# FM33FH0XX register map
File version: 1.0
CPU: SC000 r1p0, little endian, no MPU, no FPU, 3 interrupt priority bits
Registers are 32-bit, read-write, reset 0x0 unless marked. A register's access mark holds for its fields unless they carry their own. Offsets are from the block's base; [hi:lo] are bit positions; {n}, {i} and the like mark numbered series.

## GPIO_COMMON — GPIO module information
Base 0x40000E40
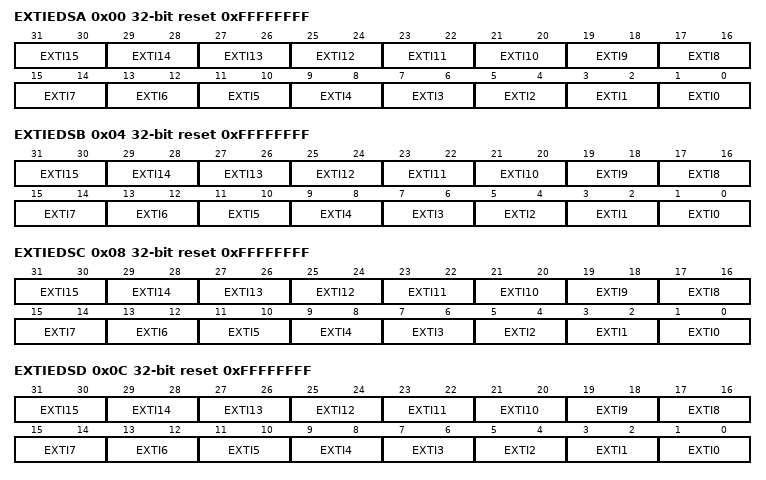
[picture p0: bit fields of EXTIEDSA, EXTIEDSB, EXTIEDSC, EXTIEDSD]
0x00 EXTIEDSA reset 0xFFFFFFFF
  [2n+1:2n] EXTI{n} (n=0..15) — EXTI{n} field description
0x04 EXTIEDSB reset 0xFFFFFFFF
  [2n+1:2n] EXTI{n} (n=0..15) — EXTI{n} field description
0x08 EXTIEDSC reset 0xFFFFFFFF
  [2n+1:2n] EXTI{n} (n=0..15) — EXTI{n} field description
0x0C EXTIEDSD reset 0xFFFFFFFF
  [2n+1:2n] EXTI{n} (n=0..15) — EXTI{n} field description
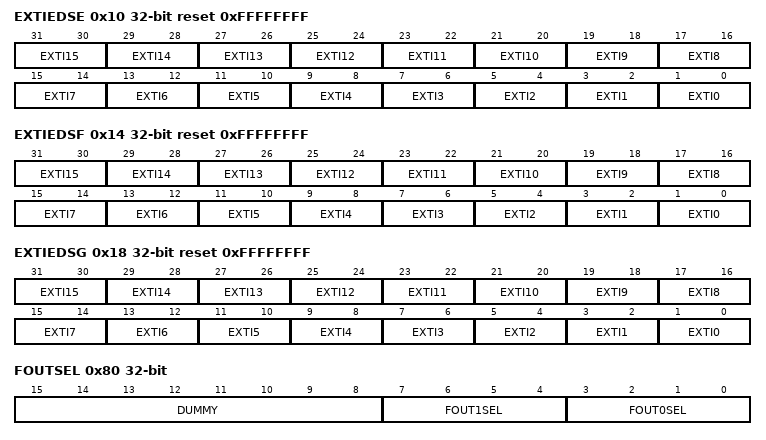
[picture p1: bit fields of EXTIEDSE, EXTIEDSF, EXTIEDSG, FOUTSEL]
0x10 EXTIEDSE reset 0xFFFFFFFF
  [2n+1:2n] EXTI{n} (n=0..15) — EXTI{n} field description
0x14 EXTIEDSF reset 0xFFFFFFFF
  [2n+1:2n] EXTI{n} (n=0..15) — EXTI{n} field description
0x18 EXTIEDSG reset 0xFFFFFFFF
  [2n+1:2n] EXTI{n} (n=0..15) — EXTI{n} field description
0x24 EXTIDFAB
  [31:0] DFAB — DFAB field description
0x28 EXTIDFCD
  [31:0] DFCD — DFCD field description
0x2C EXTIDFEF
  [31:0] DFEF — DFEF field description
0x30 EXTIDFGH
  [15:0] DFGH — DFGH field description
0x38 EXTIISRAB
  [31:0] ISRAB — ISRAB field description
0x3C EXTIISRCD
  [31:0] ISRCD — ISRCD field description
0x40 EXTIISREF
  [31:0] ISREF — ISREF field description
0x44 EXTIISRGH
  [15:0] ISRGH — ISRGH field description
0x4C EXTI_DIAB
  [31:0] DIAB — DIAB field description
0x50 EXTIDICD
  [31:0] DICD — DICD field description
0x54 EXTIDIEF
  [31:0] DIEF — DIEF field description
0x58 EXTIDIGH
  [15:0] DIGH — DIGH field description
0x80 FOUTSEL
  [15:8] DUMMY — DUMMY field description
  [7:4] FOUT1SEL — FOUT1SEL field description
  [3:0] FOUT0SEL — FOUT0SEL field description
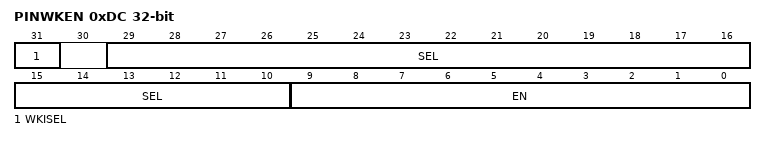
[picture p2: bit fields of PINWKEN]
0xDC PINWKEN
  [31] WKISEL — WKISEL field description
  [29:10] SEL — SEL field description
  [9:0] EN — EN field description

## GPIOA — GPIOA module information
Base 0x40000C00
Same registers: GPIOB 0x40000C40, GPIOC 0x40000C80, GPIOD 0x40000CC0, GPIOE 0x40000D00, GPIOF 0x40000D40, GPIOG 0x40000D80, GPIOH 0x40000DC0
0x00 INEN reset 0xC000
  [15:0] INEN — INEN field description
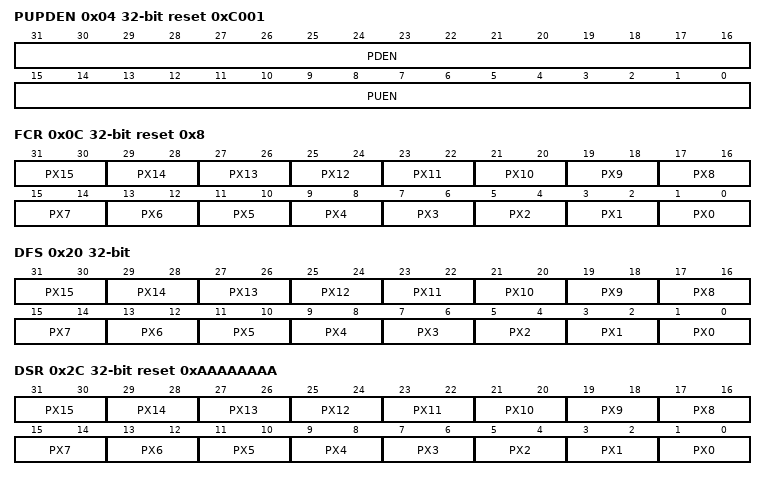
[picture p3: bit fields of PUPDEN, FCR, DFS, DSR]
0x04 PUPDEN reset 0xC001
  [31:16] PDEN — PDEN field description
  [15:0] PUEN — PUEN field description
0x08 ODEN
  [15:0] ODEN — ODEN field description
0x0C FCR reset 0x8
  [2n+1:2n] PX{n} (n=0..15) — PX{n} field description
0x10 DO
  [15:0] DO — DO field description
0x14 DSET
  [15:0] DSET wo — DSET field description
0x18 DRST
  [15:0] DRST wo — DRST field description
0x1C DIN
  [15:0] DIN ro — DIN field description
0x20 DFS
  [2n+1:2n] PX{n} (n=0..15) — PX{n} field description
0x2C DSR reset 0xAAAAAAAA
  [2n+1:2n] PX{n} (n=0..15) — PX{n} field description

## I2C0 — I2C0 module information
Base 0x40015000
Same registers: I2C1 0x40015400
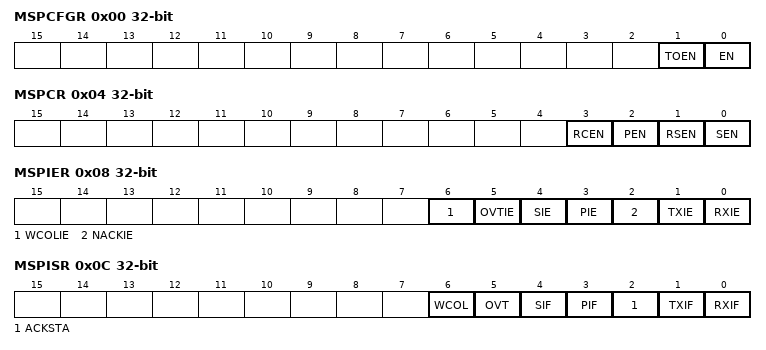
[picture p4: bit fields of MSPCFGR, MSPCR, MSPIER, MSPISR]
0x00 MSPCFGR
  [1] TOEN — TOEN field description
  [0] EN — EN field description
0x04 MSPCR
  [3] RCEN — RCEN field description
  [2] PEN — PEN field description
  [1] RSEN — RSEN field description
  [0] SEN — SEN field description
0x08 MSPIER
  [6] WCOLIE — WCOLIE field description
  [5] OVTIE — OVTIE field description
  [4] SIE — SIE field description
  [3] PIE — PIE field description
  [2] NACKIE — NACKIE field description
  [1] TXIE — TXIE field description
  [0] RXIE — RXIE field description
0x0C MSPISR
  [6] WCOL — WCOL field description
  [5] OVT — OVT field description
  [4] SIF ro — SIF field description
  [3] PIF ro — PIF field description
  [2] ACKSTA — ACKSTA field description
  [1] TXIF — TXIF field description
  [0] RXIF — RXIF field description
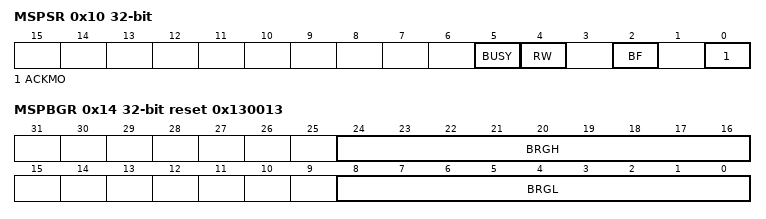
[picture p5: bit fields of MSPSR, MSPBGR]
0x10 MSPSR
  [5] BUSY ro — BUSY field description
  [4] RW ro — RW field description
  [2] BF ro — BF field description
  [0] ACKMO — ACKMO field description
0x14 MSPBGR reset 0x130013
  [24:16] BRGH — BRGH field description
  [8:0] BRGL — BRGL field description
0x18 MSPBUF
  [7:0] BUF — BUF field description
0x1C MSPTCR reset 0xA
  [8:0] SDAHD — SDAHD field description
0x20 MSPTOR reset 0xFFF
  [11:0] TIMEOUT — TIMEOUT field description
